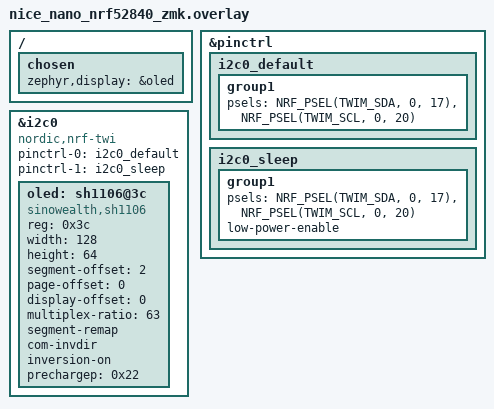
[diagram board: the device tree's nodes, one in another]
/*
 * nice!nano dongle: SH1106 OLED on I2C (SDA P0.17, SCL P0.20).
 * Applied only when building keyball39_central_dongle for nice_nano.
 */

/ {
    chosen {
        zephyr,display = &oled;
    };
};

&pinctrl {
    i2c0_default: i2c0_default {
        group1 {
            psels = <NRF_PSEL(TWIM_SDA, 0, 17)>,
                <NRF_PSEL(TWIM_SCL, 0, 20)>;
        };
    };

    i2c0_sleep: i2c0_sleep {
        group1 {
            psels = <NRF_PSEL(TWIM_SDA, 0, 17)>,
                <NRF_PSEL(TWIM_SCL, 0, 20)>;
            low-power-enable;
        };
    };
};

&i2c0 {
    status = "okay";
    compatible = "nordic,nrf-twi";
    pinctrl-0 = <&i2c0_default>;
    pinctrl-1 = <&i2c0_sleep>;
    pinctrl-names = "default", "sleep";

    oled: sh1106@3c {
        compatible = "sinowealth,sh1106";
        reg = <0x3c>;
        width = <128>;
        height = <64>;
        segment-offset = <2>;
        page-offset = <0>;
        display-offset = <0>;
        multiplex-ratio = <63>;
        segment-remap;
        com-invdir;
        inversion-on;
        prechargep = <0x22>;
    };
};
